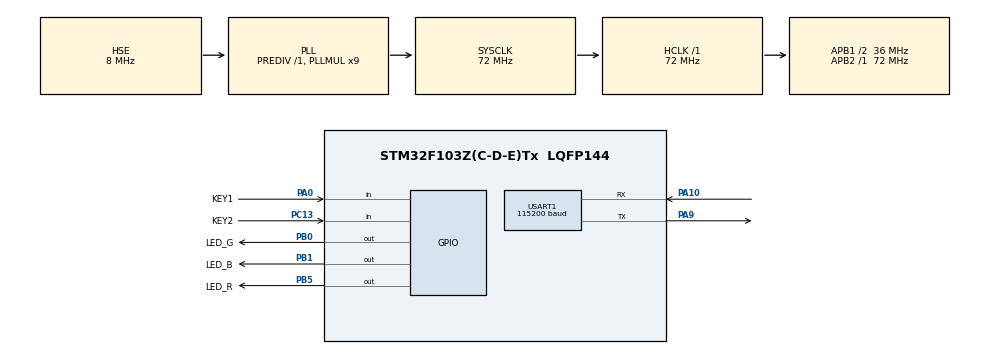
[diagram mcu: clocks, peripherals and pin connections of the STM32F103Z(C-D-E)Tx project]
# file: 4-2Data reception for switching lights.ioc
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Mcu.Family=STM32F1
Mcu.Name=STM32F103Z(C-D-E)Tx
Mcu.Package=LQFP144
NVIC.PriorityGroup=NVIC_PRIORITYGROUP_4
NVIC.USART1_IRQn=true\:10\:0\:true\:false\:true\:true\:true\:true
OSC_IN.Mode=HSE-External-Oscillator
OSC_IN.Signal=RCC_OSC_IN
OSC_OUT.Mode=HSE-External-Oscillator
OSC_OUT.Signal=RCC_OSC_OUT
PA0-WKUP.GPIO_Label=KEY1
PA0-WKUP.Signal=GPIO_Input
PA10.Mode=Asynchronous
PA10.Signal=USART1_RX
PA13.Mode=Serial_Wire
PA13.Signal=SYS_JTMS-SWDIO
PA14.Mode=Serial_Wire
PA14.Signal=SYS_JTCK-SWCLK
PA9.Mode=Asynchronous
PA9.Signal=USART1_TX
PB0.GPIO_Label=LED_G
PB0.GPIO_ModeDefaultOutputPP=GPIO_MODE_OUTPUT_PP
PB0.GPIO_Speed=GPIO_SPEED_FREQ_HIGH
PB0.PinState=GPIO_PIN_SET
PB0.Signal=GPIO_Output
PB1.GPIO_Label=LED_B
PB1.GPIO_Speed=GPIO_SPEED_FREQ_HIGH
PB1.PinState=GPIO_PIN_SET
PB1.Signal=GPIO_Output
PB5.GPIO_Label=LED_R
PB5.GPIO_Speed=GPIO_SPEED_FREQ_HIGH
PB5.PinState=GPIO_PIN_SET
PB5.Signal=GPIO_Output
PC13-TAMPER-RTC.GPIO_Label=KEY2
PC13-TAMPER-RTC.GPIO_PuPd=GPIO_NOPULL
PC13-TAMPER-RTC.Signal=GPIO_Input
PC14-OSC32_IN.Mode=LSE-External-Oscillator
PC14-OSC32_IN.Signal=RCC_OSC32_IN
PC15-OSC32_OUT.Mode=LSE-External-Oscillator
PC15-OSC32_OUT.Signal=RCC_OSC32_OUT
ProjectManager.HeapSize=0x200
ProjectManager.StackSize=0x400
ProjectManager.TargetToolchain=MDK-ARM V5
RCC.AHBFreq_Value=72000000
RCC.APB1CLKDivider=RCC_HCLK_DIV2
RCC.APB1Freq_Value=36000000
RCC.APB1TimFreq_Value=72000000
RCC.APB2Freq_Value=72000000
RCC.APB2TimFreq_Value=72000000
RCC.HCLKFreq_Value=72000000
RCC.PLLMUL=RCC_PLL_MUL9
RCC.PLLSourceVirtual=RCC_PLLSOURCE_HSE
RCC.SYSCLKFreq_VALUE=72000000
RCC.SYSCLKSource=RCC_SYSCLKSOURCE_PLLCLK
RCC.USBFreq_Value=72000000
USART1.BaudRate=115200
USART1.Mode=MODE_TX_RX
USART1.VirtualMode=VM_ASYNC
USART1.WordLength=WORDLENGTH_8B
board=custom

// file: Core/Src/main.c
/* USER CODE BEGIN Header */
/**
  ******************************************************************************
  * @file           : main.c
  * @brief          : Main program body
  ******************************************************************************
  * @attention
  *
  * Copyright (c) 2026 STMicroelectronics.
  * All rights reserved.
  *
  * This software is licensed under terms that can be found in the LICENSE file
  * in the root directory of this software component.
  * If no LICENSE file comes with this software, it is provided AS-IS.
  *
  ******************************************************************************
  */
/* USER CODE END Header */
#include "main.h"

UART_HandleTypeDef huart1;

/* USER CODE BEGIN PV */
unsigned char Uart1Temp[100]; // 定义接收缓存数组
/* USER CODE END PV */

void SystemClock_Config(void);
static void MX_GPIO_Init(void);
static void MX_USART1_UART_Init(void);

/* USER CODE BEGIN 0 */
void HAL_UART_RxCpltCallback(UART_HandleTypeDef *huart)
{
    if (huart->Instance == USART1) // 判断是否为串口1
    {
        HAL_UART_Receive_IT(&huart1, Uart1Temp, 1); // 开启串口接收中断
        HAL_UART_Transmit(&huart1, Uart1Temp, 1, 0xFFFF); // 发送接收到的数据
    }
}
/* USER CODE END 0 */

int main(void)
{

  /* MCU Configuration--------------------------------------------------------*/

  /* Reset of all peripherals, Initializes the Flash interface and the Systick. */
  HAL_Init();

  /* Configure the system clock */
  SystemClock_Config();

  /* Initialize all configured peripherals */
  MX_GPIO_Init();
  MX_USART1_UART_Init();

  /* Infinite loop */
  while (1)
  {

  }
}

void SystemClock_Config(void)
{
  RCC_OscInitTypeDef RCC_OscInitStruct = {0};
  RCC_ClkInitTypeDef RCC_ClkInitStruct = {0};

  /** Initializes the RCC Oscillators according to the specified parameters
  * in the RCC_OscInitTypeDef structure.
  */
  RCC_OscInitStruct.OscillatorType = RCC_OSCILLATORTYPE_HSE;
  RCC_OscInitStruct.HSEState = RCC_HSE_ON;
  RCC_OscInitStruct.HSEPredivValue = RCC_HSE_PREDIV_DIV1;
  RCC_OscInitStruct.HSIState = RCC_HSI_ON;
  RCC_OscInitStruct.PLL.PLLState = RCC_PLL_ON;
  RCC_OscInitStruct.PLL.PLLSource = RCC_PLLSOURCE_HSE;
  RCC_OscInitStruct.PLL.PLLMUL = RCC_PLL_MUL9;
  if (HAL_RCC_OscConfig(&RCC_OscInitStruct) != HAL_OK)
  {
    Error_Handler();
  }

  /** Initializes the CPU, AHB and APB buses clocks
  */
  RCC_ClkInitStruct.ClockType = RCC_CLOCKTYPE_HCLK|RCC_CLOCKTYPE_SYSCLK
                              |RCC_CLOCKTYPE_PCLK1|RCC_CLOCKTYPE_PCLK2;
  RCC_ClkInitStruct.SYSCLKSource = RCC_SYSCLKSOURCE_PLLCLK;
  RCC_ClkInitStruct.AHBCLKDivider = RCC_SYSCLK_DIV1;
  RCC_ClkInitStruct.APB1CLKDivider = RCC_HCLK_DIV2;
  RCC_ClkInitStruct.APB2CLKDivider = RCC_HCLK_DIV1;

  if (HAL_RCC_ClockConfig(&RCC_ClkInitStruct, FLASH_LATENCY_2) != HAL_OK)
  {
    Error_Handler();
  }
}

static void MX_USART1_UART_Init(void)
{

  huart1.Instance = USART1;
  huart1.Init.BaudRate = 115200;
  huart1.Init.WordLength = UART_WORDLENGTH_8B;
  huart1.Init.StopBits = UART_STOPBITS_1;
  huart1.Init.Parity = UART_PARITY_NONE;
  huart1.Init.Mode = UART_MODE_TX_RX;
  huart1.Init.HwFlowCtl = UART_HWCONTROL_NONE;
  huart1.Init.OverSampling = UART_OVERSAMPLING_16;
  if (HAL_UART_Init(&huart1) != HAL_OK)
  {
    Error_Handler();
  }
  /* USER CODE BEGIN USART1_Init 2 */
  HAL_UART_Receive_IT(&huart1, Uart1Temp, 1); // 开启串口1接收中断，接收数据存放在Uart1Temp数组中，长度为1字节
  /* USER CODE END USART1_Init 2 */

}

static void MX_GPIO_Init(void)
{
  GPIO_InitTypeDef GPIO_InitStruct = {0};

  /* GPIO Ports Clock Enable */
  __HAL_RCC_GPIOC_CLK_ENABLE();
  __HAL_RCC_GPIOA_CLK_ENABLE();
  __HAL_RCC_GPIOB_CLK_ENABLE();

  /*Configure GPIO pin Output Level */
  HAL_GPIO_WritePin(GPIOB, LED_G_Pin|LED_B_Pin|LED_R_Pin, GPIO_PIN_SET);

  /*Configure GPIO pin : KEY2_Pin */
  GPIO_InitStruct.Pin = KEY2_Pin;
  GPIO_InitStruct.Mode = GPIO_MODE_INPUT;
  GPIO_InitStruct.Pull = GPIO_NOPULL;
  HAL_GPIO_Init(KEY2_GPIO_Port, &GPIO_InitStruct);

  /*Configure GPIO pin : KEY1_Pin */
  GPIO_InitStruct.Pin = KEY1_Pin;
  GPIO_InitStruct.Mode = GPIO_MODE_INPUT;
  GPIO_InitStruct.Pull = GPIO_NOPULL;
  HAL_GPIO_Init(KEY1_GPIO_Port, &GPIO_InitStruct);

  /*Configure GPIO pins : LED_G_Pin LED_B_Pin LED_R_Pin */
  GPIO_InitStruct.Pin = LED_G_Pin|LED_B_Pin|LED_R_Pin;
  GPIO_InitStruct.Mode = GPIO_MODE_OUTPUT_PP;
  GPIO_InitStruct.Pull = GPIO_NOPULL;
  GPIO_InitStruct.Speed = GPIO_SPEED_FREQ_HIGH;
  HAL_GPIO_Init(GPIOB, &GPIO_InitStruct);

}

void Error_Handler(void)
{
  __disable_irq();
  while (1)
  {
  }
}
